# STM32WBA64 register map
File version: 1.1
CPU: CM33 r0p1, little endian, MPU, FPU, 4 interrupt priority bits
Registers are 32-bit, read-write, reset 0x0 unless marked. A register's access mark holds for its fields unless they carry their own. Offsets are from the block's base; [hi:lo] are bit positions; {n}, {i} and the like mark numbered series.

## EXTI — EXTI address block description
Base 0x46022000
Same registers: SEC_EXTI 0x56022000
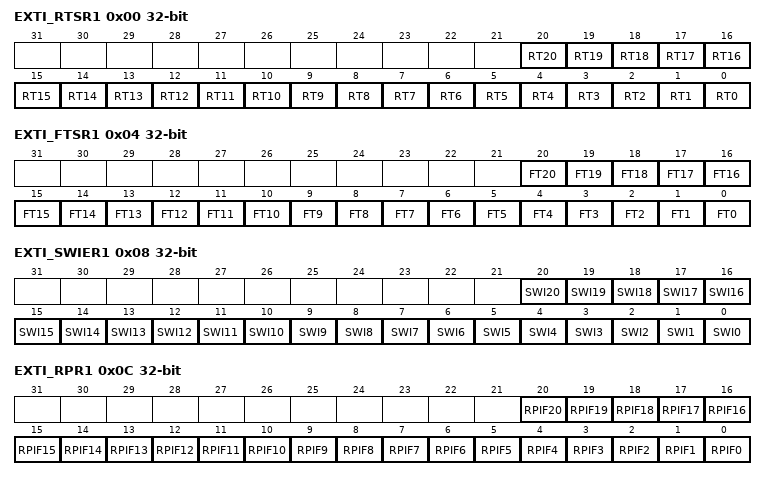
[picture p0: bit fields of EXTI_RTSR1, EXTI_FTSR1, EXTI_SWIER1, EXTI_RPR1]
0x00 EXTI_RTSR1 — EXTI rising trigger selection register
  [all] fields
    0=Rising trigger disabled (for event and interrupt) for input line; 1=Rising trigger enabled (for event and interrupt) for input line
  [n] RT{n} (n=0..20) — Rising trigger event configuration bit of configurable event input x
0x04 EXTI_FTSR1 — EXTI falling trigger selection register
  [all] fields
    0=Falling trigger disabled (for event and Interrupt) for input line; 1=Falling trigger enabled (for event and Interrupt) for input line
  [n] FT{n} (n=0..20) — Falling trigger event configuration bit of configurable event input x
0x08 EXTI_SWIER1 — EXTI software interrupt event register
  [all] fields
    0=Writing 0 has no effect; 1=Writing 1 triggers a rising edge event on event x
  [n] SWI{n} (n=0..20) — Software interrupt on event x
0x0C EXTI_RPR1 — EXTI rising edge pending register
  [all] fields
    0=No rising edge trigger request occurred; 1=Rising edge trigger request occurred
  [n] RPIF{n} (n=0..20) — configurable event inputs x rising edge pending bit
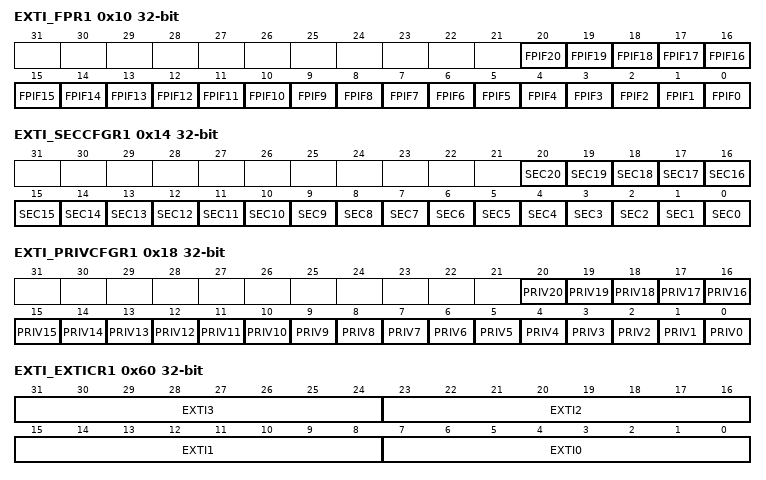
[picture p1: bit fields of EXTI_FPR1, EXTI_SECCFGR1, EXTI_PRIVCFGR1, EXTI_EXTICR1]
0x10 EXTI_FPR1 — EXTI falling edge pending register
  [all] fields
    0=No falling edge trigger request occurred; 1=Falling edge trigger request occurred
  [n] FPIF{n} (n=0..20) — configurable event inputs x falling edge pending bit
0x14 EXTI_SECCFGR1 — EXTI security configuration register
  [all] fields
    0=Event security disabled (non-secure); 1=Event security enabled (secure)
  [n] SEC{n} (n=0..20) — Security enable on event input x
0x18 EXTI_PRIVCFGR1 — EXTI privilege configuration register
  [all] fields
    0=Event privilege disabled (unprivileged); 1=Event privilege enabled (privileged)
  [n] PRIV{n} (n=0..20) — Security enable on event input x
0x60 EXTI_EXTICR1 — EXTI external interrupt selection register
  [31:24] EXTI3 — EXTI3 GPIO port selection on interconnect exti3
    0=PA3 pin; 1=PB3 pin; 2=PC3 pin; 3=PD3 pin; 4=PE3 pin; 6=PG3 pin; 7=PH3 pin
  [23:16] EXTI2 — EXTI2 GPIO port selection on interconnect exti2
    0=PA2 pin; 1=PB2 pin; 2=PC2 pin; 3=PD2 pin; 4=PE2 pin; 6=PG2 pin
  [15:8] EXTI1 — EXTI1 GPIO port selection on interconnect exti1
    0=PA1 pin; 1=PB1 pin; 2=PC1 pin; 3=PD1 pin; 4=PE1 pin
  [7:0] EXTI0 — EXTI0 GPIO port selection on interconnect exti0
    0=PA0 pin; 1=PB0 pin; 2=PC0 pin; 3=PD0 pin; 4=PE0 pin
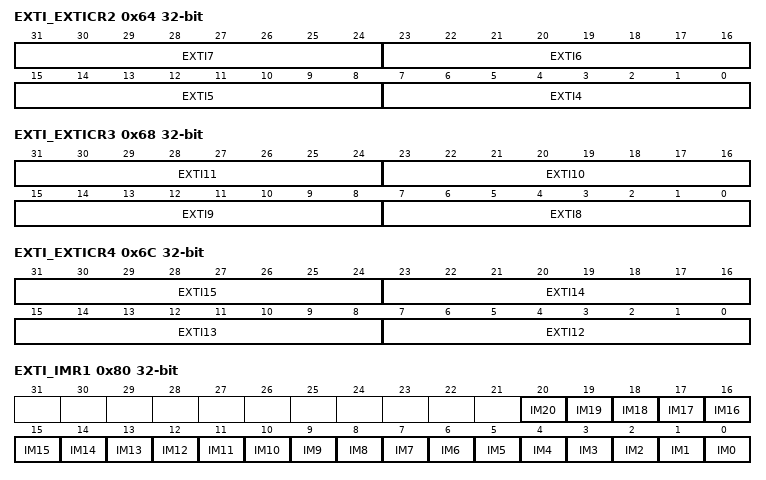
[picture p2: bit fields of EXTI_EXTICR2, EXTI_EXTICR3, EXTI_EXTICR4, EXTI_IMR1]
0x64 EXTI_EXTICR2 — EXTI external interrupt selection register
  [31:24] EXTI7 — EXTI7 GPIO port selection on interconnect exti7
    0=PA7 pin; 1=PB7 pin; 2=PC7 pin; 3=PD7 pin; 6=PG7 pin
  [23:16] EXTI6 — EXTI6 GPIO port selection on interconnect exti6
    0=PA6 pin; 1=PB6 pin; 2=PC6 pin; 3=PD6 pin; 4=PE6 pin; 6=PG6 pin
  [15:8] EXTI5 — EXTI5 GPIO port selection on interconnect exti5
    0=PA5 pin; 1=PB5 pin; 2=PC5 pin; 3=PD5 pin; 4=PE5 pin; 6=PG5 pin
  [7:0] EXTI4 — EXTI4 GPIO port selection on interconnect exti4
    0=PA4 pin; 1=PB4 pin; 2=PC4 pin; 3=PD4 pin; 4=PE4 pin; 6=PG4 pin
0x68 EXTI_EXTICR3 — EXTI external interrupt selection register
  [8n-57:8n-64] EXTI{n} (n=8..11) — EXTI{n} GPIO port selection on interconnect exti{n}
    0=PA{n} pin; 1=PB{n} pin; 2=PC{n} pin; 3=PD{n} pin; 6=PG{n} pin
0x6C EXTI_EXTICR4 — EXTI external interrupt selection register
  [31:24] EXTI15 — EXTI15 GPIO port selection on interconnect exti15
    0=PA15 pin; 1=PB15 pin; 2=PC15 pin; 3=PD15 pin; 6=PG15 pin
  [23:16] EXTI14 — EXTI14 GPIO port selection on interconnect exti14
    0=PA14 pin; 1=PB14 pin; 2=PC14 pin; 3=PD14 pin; 6=PG14 pin
  [15:8] EXTI13 — EXTI13 GPIO port selection on interconnect exti13
    0=PA13 pin; 1=PB13 pin; 2=PC13 pin; 3=PD13 pin; 6=PG13 pin
  [7:0] EXTI12 — EXTI0 GPIO port selection on interconnect exti12
    0=PA12 pin; 1=PB12 pin; 2=PC12 pin; 3=PD12 pin; 6=PG12 pin
0x70 EXTI_LOCKR — EXTI lock register
  [0] LOCK — Global security and privilege configuration registers (EXTI_SECCFGR and EXTI_PRIVCFGR) lock
    0=Security and privilege configuration open, can be modified; 1=Security and privilege configuration locked, can no longer be modified
0x80 EXTI_IMR1 — EXTI CPU wake-up with interrupt mask register
  [all] fields
    0=Wake-up with interrupt request from input event x is masked; 1=Wake-up with interrupt request from input event x is unmasked
  [n] IM{n} (n=0..20) — CPU wake-up with interrupt mask on event input x
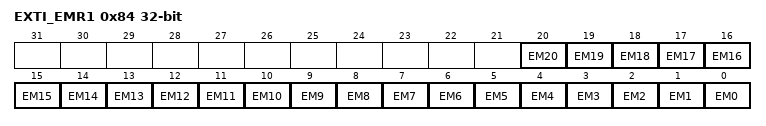
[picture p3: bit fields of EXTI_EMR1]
0x84 EXTI_EMR1 — EXTI CPU wake-up with event mask register
  [all] fields
    0=Wake-up with event generation from Line x is masked; 1=Wake-up with event generation from Line x is unmasked
  [n] EM{n} (n=0..20) — CPU wake-up with event generation mask on event input x

## Notices in the file
Copyright (c) 2025 STMicroelectronics.
SPDX-License-Identifier: Apache-2.0
Licensed under the Apache License, Version 2.0 (the "License");
you may not use this file except in compliance with the License.
You may obtain a copy of the License at
http://www.apache.org/licenses/LICENSE-2.0
Unless required by applicable law or agreed to in writing, software
distributed under the License is distributed on an "AS IS" BASIS,
WITHOUT WARRANTIES OR CONDITIONS OF ANY KIND, either express or implied.
See the License for the specific language governing permissions and
limitations under the License.
